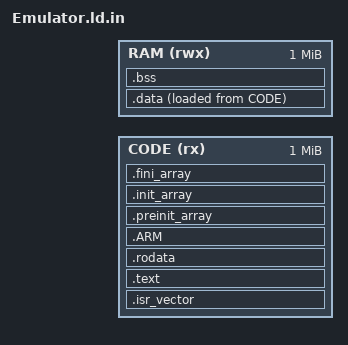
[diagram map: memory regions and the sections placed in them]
ENTRY(Reset_Handler)

MEMORY
{
    CODE (rx) : ORIGIN = @EMULATOR_CODE@, LENGTH = 1024K
    RAM (rwx) : ORIGIN = @EMULATOR_RAM@, LENGTH = 1024K
}

_estack = ORIGIN(RAM) + LENGTH(RAM);
_mainstacklimit = _estack - 16K;

SECTIONS
{
    .isr_vector :
    {
        . = ALIGN(4);
        KEEP(*(.isr_vector))
        . = ALIGN(4);
    } > CODE

    .text :
    {
        . = ALIGN(4);
        *(.text)
        *(.text*)
        KEEP(*(.init))
        KEEP(*(.fini))
        . = ALIGN(4);
    } > CODE

    .rodata :
    {
        . = ALIGN(4);
        *(.rodata)
        *(.rodata*)
        . = ALIGN(4);
    } > CODE

    .ARM :
    {
        *(.ARM.exidx*)
    } > CODE

    .preinit_array :
    {
        PROVIDE_HIDDEN(__preinit_array_start = .);
        KEEP(*(.preinit_array*))
        PROVIDE_HIDDEN(__preinit_array_end = .);
    } > CODE

    .init_array :
    {
        PROVIDE_HIDDEN(__init_array_start = .);
        KEEP(*(SORT(.init_array.*)))
        KEEP(*(.init_array*))
        PROVIDE_HIDDEN(__init_array_end = .);
    } > CODE

    .fini_array :
    {
        PROVIDE_HIDDEN(__fini_array_start = .);
        KEEP(*(SORT(.fini_array.*)))
        KEEP(*(.fini_array*))
        PROVIDE_HIDDEN(__fini_array_end = .);
    } > CODE

    _sidata = LOADADDR(.data);

    .data :
    {
        . = ALIGN(4);
        _sdata = .;
        *(.data)
        *(.data*)
        . = ALIGN(4);
        _edata = .;
    } > RAM AT> CODE

    .bss :
    {
        . = ALIGN(4);
        _sbss = .;
        __bss_start__ = _sbss;
        *(.bss)
        *(.bss*)
        *(COMMON)
        . = ALIGN(4);
        _ebss = .;
        __bss_end__ = _ebss;
    } > RAM

    PROVIDE(end = _ebss);
    PROVIDE(_end = _ebss);

    ASSERT(_ebss <= _mainstacklimit, "the data of the image runs into the main stack")

    .ARM.attributes 0 : { *(.ARM.attributes) }
}
